# AT32F425xx_v2 register map
Vendor: Keil; Series: AT32F425; File version: 1.0
CPU: CM4 r0p1, little endian, no MPU, FPU, 4 interrupt priority bits
Registers are 32-bit, read-write, reset 0x0 unless marked. A register's access mark holds for its fields unless they carry their own. Offsets are from the block's base; [hi:lo] are bit positions; {n}, {i} and the like mark numbered series.

## PWC — Power control
Base 0x40007000
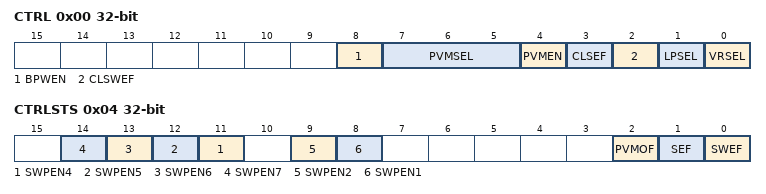
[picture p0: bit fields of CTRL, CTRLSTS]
0x00 CTRL — Power control register (PWC_CTRL)
  [8] BPWEN — Battery power domain write enable
  [7:5] PVMSEL — Power voltage monitoring boundary select
  [4] PVMEN — Power voltage monitoring enable
  [3] CLSEF wo — Clear SEF flag
  [2] CLSWEF wo — Clear SWEF flag
  [1] LPSEL — Low power mode select when Cortex-M4 sleepdeep
  [0] VRSEL — Voltage regulator state select when deepsleep mode
0x04 CTRLSTS — Power control register (PWC_CTRLSTS)
  [n+7] SWPEN{n} (n=4..7) — Standby wake-up pin{n} enable
  [9] SWPEN2 — Standby wake-up pin2 enable
  [8] SWPEN1 — Standby wake-up pin1 enable
  [2] PVMOF ro — Power voltage monitoring output flag
  [1] SEF ro — Standby mode entry flag
  [0] SWEF ro — Standby wake-up event flag
0x20 CTRL2 — Power control register 2 (PWC_CTRL2)
  [5] VREXLPEN — Voltage regulator extra low power mode enable

## GPIOA — General purpose I/Os
Base 0x48000000
Same registers: GPIOB 0x48000400, GPIOC 0x48000800, GPIOD 0x48000C00, GPIOF 0x48001400
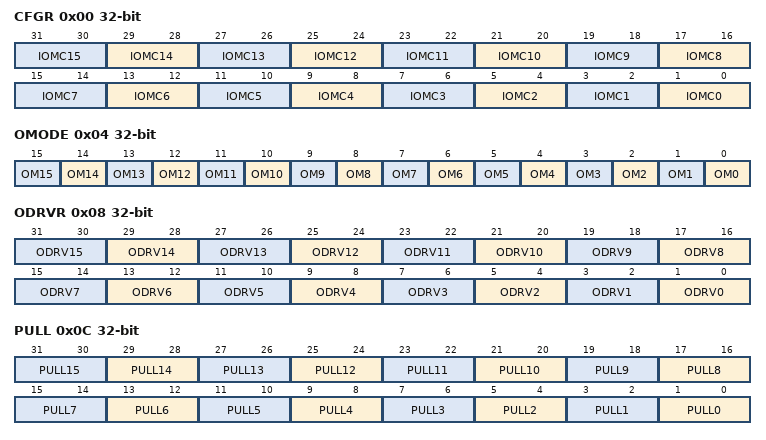
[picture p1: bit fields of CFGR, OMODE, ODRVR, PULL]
0x00 CFGR — GPIO configuration register
  [2n+1:2n] IOMC{n} (n=0..15) — GPIOx pin {n} mode configurate
0x04 OMODE — GPIO output mode register
  [n] OM{n} (n=0..15) — GPIOx pin {n} outpu mode configurate
0x08 ODRVR — GPIO drive capability register
  [2n+1:2n] ODRV{n} (n=0..15) — GPIOx pin {n} output drive capability
0x0C PULL — GPIO pull-up/pull-down register
  [2n+1:2n] PULL{n} (n=0..15) — GPIOx pin {n} pull configuration
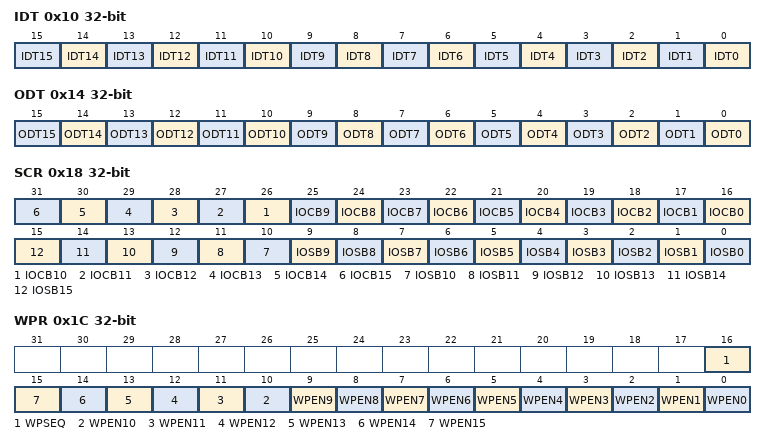
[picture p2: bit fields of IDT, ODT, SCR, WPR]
0x10 IDT ro — GPIO input data register
  [n] IDT{n} (n=0..15) — Port input data
0x14 ODT — GPIO output data register
  [n] ODT{n} (n=0..15) — Port output data
0x18 SCR wo — Port bit set/clear register
  [n+16] IOCB{n} (n=0..15) — Clear bit {n}
  [n] IOSB{n} (n=3..15) — Set bit {n}
  [2] IOSB2 — Set bit 1
  [1] IOSB1 — Set bit 1
  [0] IOSB0 — Set bit 0
0x1C WPR — Port write protect register
  [16] WPSEQ — Write protect sequence
  [n] WPEN{n} (n=0..15) — Write protect enable {n}
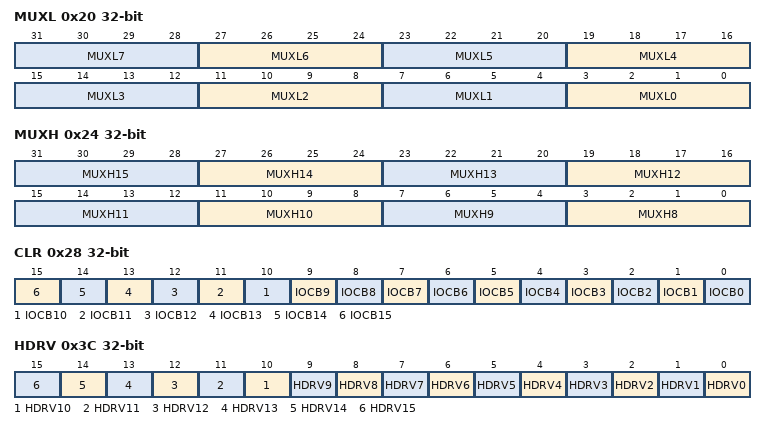
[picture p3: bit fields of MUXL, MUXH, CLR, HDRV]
0x20 MUXL — GPIO muxing function low register
  [4n+3:4n] MUXL{n} (n=0..7) — GPIOx pin {n} muxing
0x24 MUXH — GPIO muxing function high register
  [4n-29:4n-32] MUXH{n} (n=8..15) — GPIOx pin {n} muxing
0x28 CLR wo — GPIO bit reset register
  [n] IOCB{n} (n=3..15) — Clear bit {n}
  [2] IOCB2 — Clear bit 1
  [1] IOCB1 — Clear bit 1
  [0] IOCB0 — Clear bit 0
0x3C HDRV — Huge current driver
  [n] HDRV{n} (n=0..15) — Port x driver bit y

## EXINT
Base 0x40010400
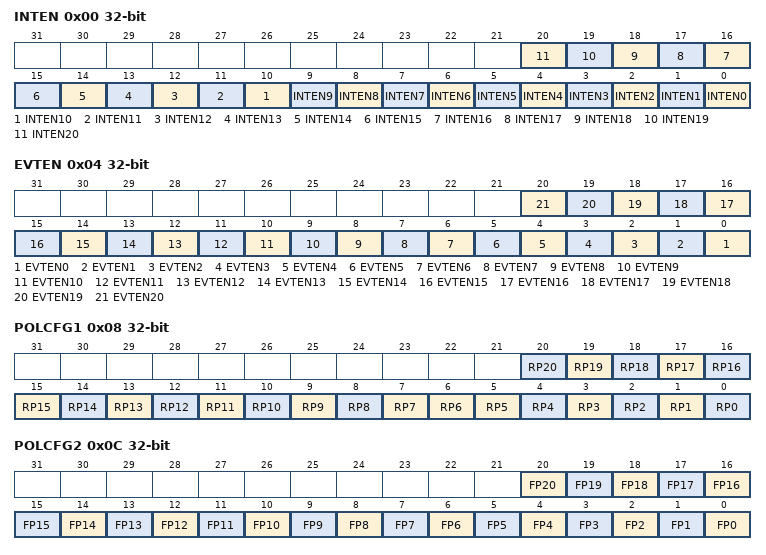
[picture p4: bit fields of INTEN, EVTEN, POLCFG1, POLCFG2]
0x00 INTEN — Interrupt enable register (EXTINT_INTEN)
  [n] INTEN{n} (n=0..20) — Interrupt enable or disable on line {n}
0x04 EVTEN — Event enable register (EXTINT_EVTEN)
  [n] EVTEN{n} (n=0..20) — Event enable or disable on line {n}
0x08 POLCFG1 — Rising polarity configuration register(EXTINT_POLCFG1)
  [n] RP{n} (n=7..20) — Rising polarity configuration bit of line {n}
  [6] RP6 — Rising polarity configuration bit of linee 6
  [n] RP{n} (n=0..5) — Rising polarity configuration bit of line {n}
0x0C POLCFG2 — Falling polarity configuration register(EXTINT_POLCFG2)
  [n] FP{n} (n=0..20) — Falling polarity event configuration bit of line {n}
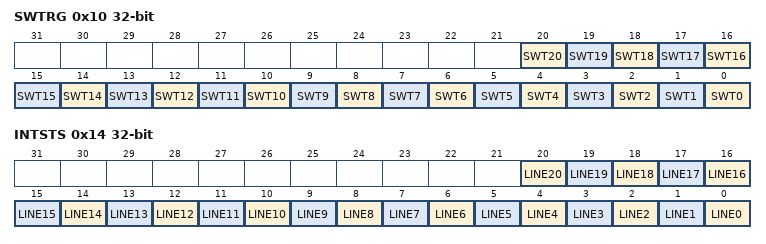
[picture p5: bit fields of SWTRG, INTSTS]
0x10 SWTRG — Software triggle register (EXTINT_SWIE)
  [n] SWT{n} (n=0..20) — Software triggle on line {n}
0x14 INTSTS — Interrupt status register (EXTINT_INTSTS)
  [n] LINE{n} (n=0..20) — Line {n} state bit

## WDT — Watchdog
Base 0x40003000
0x00 CMD wo — Command register
  [15:0] CMD
0x04 DIV — Division register
  [2:0] DIV — Division divider
0x08 RLD reset 0xFFF — Reload register
  [11:0] RLD — Reload value
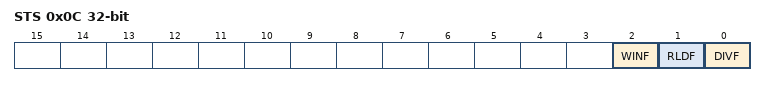
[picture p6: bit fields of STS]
0x0C STS ro — Status register
  [2] WINF — Window value update complete flag
  [1] RLDF — Reload value update complete flag
  [0] DIVF — Division value update complete flag
0x10 WIN reset 0xFFF — Window register
  [11:0] WIN — Window value
